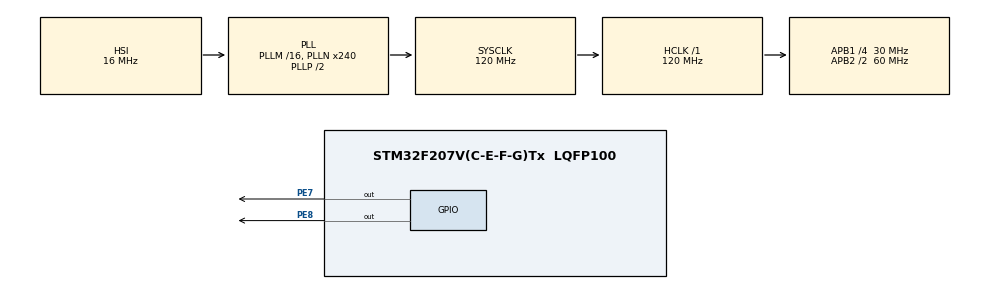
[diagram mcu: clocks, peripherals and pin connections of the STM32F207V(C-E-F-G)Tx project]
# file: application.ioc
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Mcu.Family=STM32F2
RCC.CortexFreq_Value=120000000
RCC.APB1CLKDivider=RCC_HCLK_DIV4
RCC.SYSCLKSource=RCC_SYSCLKSOURCE_PLLCLK
ProjectManager.StackSize=0x400
ProjectManager.TargetToolchain=STM32CubeIDE
RCC.HCLKFreq_Value=120000000
RCC.APB2TimFreq_Value=120000000
RCC.LSE_VALUE=32768
RCC.AHBFreq_Value=120000000
RCC.HSE_VALUE=25000000
board=custom
RCC.VCOOutputFreq_Value=240000000
RCC.APB2Freq_Value=60000000
PE8.Signal=GPIO_Output
Mcu.Name=STM32F207V(C-E-F-G)Tx
RCC.48MHZClocksFreq_Value=60000000
RCC.SYSCLKFreq_VALUE=120000000
Mcu.Package=LQFP100
ProjectManager.HeapSize=0x200
RCC.HSI_VALUE=16000000
NVIC.PriorityGroup=NVIC_PRIORITYGROUP_4
RCC.APB2CLKDivider=RCC_HCLK_DIV2
RCC.PLLN=240
RCC.APB1TimFreq_Value=60000000
PE7.Signal=GPIO_Output
RCC.APB1Freq_Value=30000000

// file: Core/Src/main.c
/* USER CODE BEGIN Header */
/**
  ******************************************************************************
  * @file           : main.c
  * @brief          : Main program body
  ******************************************************************************
  * @attention
  *
  * <h2><center>&copy; Copyright (c) 2021 STMicroelectronics.
  * All rights reserved.</center></h2>
  *
  * This software component is licensed by ST under BSD 3-Clause license,
  * the "License"; You may not use this file except in compliance with the
  * License. You may obtain a copy of the License at:
  *                        opensource.org/licenses/BSD-3-Clause
  *
  ******************************************************************************
  */
/* USER CODE END Header */
#include "main.h"

void SystemClock_Config(void);
static void MX_GPIO_Init(void);

int main(void)
{

  /* MCU Configuration--------------------------------------------------------*/

  /* Reset of all peripherals, Initializes the Flash interface and the Systick. */
  HAL_Init();

  /* Configure the system clock */
  SystemClock_Config();

  /* Initialize all configured peripherals */
  MX_GPIO_Init();

  /* Infinite loop */
  /* USER CODE BEGIN WHILE */
#pragma clang diagnostic push
#pragma ide diagnostic ignored "EndlessLoop"
    while (1) {
        HAL_GPIO_TogglePin(GPIOE, GPIO_PIN_8);
        HAL_Delay(250);
    /* USER CODE END WHILE */

    /* USER CODE BEGIN 3 */
    }
#pragma clang diagnostic pop
  /* USER CODE END 3 */
}

void SystemClock_Config(void)
{
  RCC_OscInitTypeDef RCC_OscInitStruct = {0};
  RCC_ClkInitTypeDef RCC_ClkInitStruct = {0};

  /** Initializes the RCC Oscillators according to the specified parameters
  * in the RCC_OscInitTypeDef structure.
  */
  RCC_OscInitStruct.OscillatorType = RCC_OSCILLATORTYPE_HSI;
  RCC_OscInitStruct.HSIState = RCC_HSI_ON;
  RCC_OscInitStruct.HSICalibrationValue = RCC_HSICALIBRATION_DEFAULT;
  RCC_OscInitStruct.PLL.PLLState = RCC_PLL_ON;
  RCC_OscInitStruct.PLL.PLLSource = RCC_PLLSOURCE_HSI;
  RCC_OscInitStruct.PLL.PLLM = 16;
  RCC_OscInitStruct.PLL.PLLN = 240;
  RCC_OscInitStruct.PLL.PLLP = RCC_PLLP_DIV2;
  RCC_OscInitStruct.PLL.PLLQ = 4;
  if (HAL_RCC_OscConfig(&RCC_OscInitStruct) != HAL_OK)
  {
    Error_Handler();
  }
  /** Initializes the CPU, AHB and APB buses clocks
  */
  RCC_ClkInitStruct.ClockType = RCC_CLOCKTYPE_HCLK|RCC_CLOCKTYPE_SYSCLK
                              |RCC_CLOCKTYPE_PCLK1|RCC_CLOCKTYPE_PCLK2;
  RCC_ClkInitStruct.SYSCLKSource = RCC_SYSCLKSOURCE_PLLCLK;
  RCC_ClkInitStruct.AHBCLKDivider = RCC_SYSCLK_DIV1;
  RCC_ClkInitStruct.APB1CLKDivider = RCC_HCLK_DIV4;
  RCC_ClkInitStruct.APB2CLKDivider = RCC_HCLK_DIV2;

  if (HAL_RCC_ClockConfig(&RCC_ClkInitStruct, FLASH_LATENCY_3) != HAL_OK)
  {
    Error_Handler();
  }
}

static void MX_GPIO_Init(void)
{
  GPIO_InitTypeDef GPIO_InitStruct = {0};

  /* GPIO Ports Clock Enable */
  __HAL_RCC_GPIOE_CLK_ENABLE();

  /*Configure GPIO pin Output Level */
  HAL_GPIO_WritePin(GPIOE, GPIO_PIN_7|GPIO_PIN_8, GPIO_PIN_RESET);

  /*Configure GPIO pins : PE7 PE8 */
  GPIO_InitStruct.Pin = GPIO_PIN_7|GPIO_PIN_8;
  GPIO_InitStruct.Mode = GPIO_MODE_OUTPUT_PP;
  GPIO_InitStruct.Pull = GPIO_NOPULL;
  GPIO_InitStruct.Speed = GPIO_SPEED_FREQ_LOW;
  HAL_GPIO_Init(GPIOE, &GPIO_InitStruct);

}

void Error_Handler(void)
{
    __disable_irq();
    while (1) {
    }
}

/************************ (C) COPYRIGHT STMicroelectronics *****END OF FILE****/
